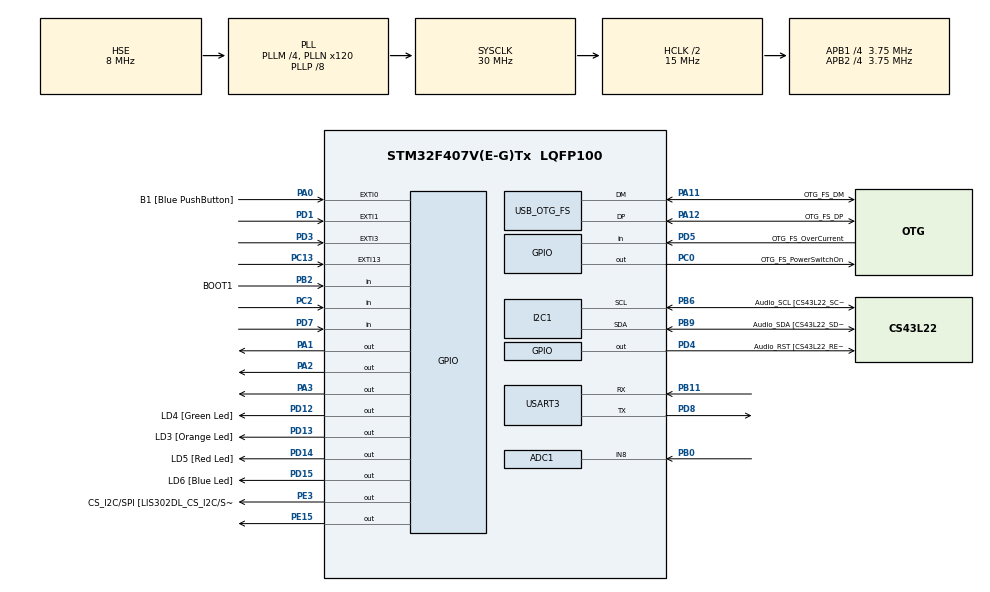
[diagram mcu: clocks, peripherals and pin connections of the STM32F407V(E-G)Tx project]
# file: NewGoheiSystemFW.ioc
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ADC1.Channel-32\#ChannelRegularConversion=ADC_CHANNEL_8
ADC1.ClockPrescaler=ADC_CLOCK_SYNC_PCLK_DIV2
ADC1.ContinuousConvMode=DISABLE
ADC1.DMAContinuousRequests=DISABLE
ADC1.DataAlign=ADC_DATAALIGN_RIGHT
ADC1.DiscontinuousConvMode=DISABLE
ADC1.EOCSelection=ADC_EOC_SINGLE_CONV
ADC1.EnableAnalogWatchDog=false
ADC1.ExternalTrigConv=ADC_SOFTWARE_START
ADC1.ExternalTrigConvEdge=ADC_EXTERNALTRIGCONVEDGE_NONE
ADC1.InjNumberOfConversion=0
ADC1.NbrOfConversion=1
ADC1.NbrOfConversionFlag=1
ADC1.Rank-32\#ChannelRegularConversion=1
ADC1.Resolution=ADC_RESOLUTION_12B
ADC1.SamplingTime-32\#ChannelRegularConversion=ADC_SAMPLETIME_3CYCLES
ADC1.ScanConvMode=DISABLE
ADC1.master=1
Dma.Request0=USART3_RX
Dma.USART3_RX.0.Direction=DMA_PERIPH_TO_MEMORY
Dma.USART3_RX.0.FIFOMode=DMA_FIFOMODE_DISABLE
Dma.USART3_RX.0.Instance=DMA1_Stream1
Dma.USART3_RX.0.MemDataAlignment=DMA_MDATAALIGN_BYTE
Dma.USART3_RX.0.MemInc=DMA_MINC_ENABLE
Dma.USART3_RX.0.Mode=DMA_CIRCULAR
Dma.USART3_RX.0.PeriphDataAlignment=DMA_PDATAALIGN_BYTE
Dma.USART3_RX.0.PeriphInc=DMA_PINC_DISABLE
Dma.USART3_RX.0.Priority=DMA_PRIORITY_LOW
Mcu.Family=STM32F4
Mcu.Name=STM32F407V(E-G)Tx
Mcu.Package=LQFP100
NVIC.ADC_IRQn=true\:0\:1\:false\:false\:true\:true
NVIC.DMA1_Stream1_IRQn=true\:0\:0\:false\:false\:true\:false
NVIC.EXTI15_10_IRQn=true\:0\:0\:false\:false\:true\:true
NVIC.EXTI1_IRQn=true\:0\:0\:false\:false\:true\:true
NVIC.EXTI3_IRQn=true\:0\:0\:false\:false\:true\:true
NVIC.OTG_FS_IRQn=true\:0\:0\:false\:false\:true\:false
NVIC.PriorityGroup=NVIC_PRIORITYGROUP_0
NVIC.TIM2_IRQn=true\:0\:0\:false\:false\:true\:true
NVIC.TIM3_IRQn=true\:0\:2\:true\:false\:true\:true
NVIC.TIM4_IRQn=true\:0\:0\:false\:false\:true\:true
PA0-WKUP.GPIO_Label=B1 [Blue PushButton]
PA0-WKUP.Signal=GPXTI0
PA1.Signal=GPIO_Output
PA10.GPIO_Label=OTG_FS_ID
PA10.GPIO_Mode=GPIO_MODE_AF_PP
PA10.GPIO_PuPd=GPIO_NOPULL
PA10.GPIO_Speed=GPIO_SPEED_FREQ_LOW
PA10.Signal=USB_OTG_FS_ID
PA11.GPIO_Label=OTG_FS_DM
PA11.GPIO_Mode=GPIO_MODE_AF_PP
PA11.GPIO_PuPd=GPIO_NOPULL
PA11.GPIO_Speed=GPIO_SPEED_FREQ_LOW
PA11.Mode=Device_Only
PA11.Signal=USB_OTG_FS_DM
PA12.GPIO_Label=OTG_FS_DP
PA12.GPIO_Mode=GPIO_MODE_AF_PP
PA12.GPIO_PuPd=GPIO_NOPULL
PA12.GPIO_Speed=GPIO_SPEED_FREQ_LOW
PA12.Mode=Device_Only
PA12.Signal=USB_OTG_FS_DP
PA13.GPIO_Label=SWDIO
PA13.Signal=SYS_JTMS-SWDIO
PA14.GPIO_Label=SWCLK
PA14.Signal=SYS_JTCK-SWCLK
PA2.Signal=GPIO_Output
PA3.Signal=GPIO_Output
PA4.GPIO_Label=I2S3_WS [CS43L22_LRCK]
PA4.GPIO_Mode=GPIO_MODE_AF_PP
PA4.GPIO_PuPd=GPIO_NOPULL
PA4.GPIO_Speed=GPIO_SPEED_FREQ_LOW
PA4.Signal=I2S3_WS
PA5.GPIO_Label=SPI1_SCK [LIS302DL_SCL/SPC]
PA5.GPIO_Mode=GPIO_MODE_AF_PP
PA5.GPIO_PuPd=GPIO_NOPULL
PA5.GPIO_Speed=GPIO_SPEED_FREQ_LOW
PA5.Signal=SPI1_SCK
PA6.GPIO_Label=SPI1_MISO [LIS302DL_SDO]
PA6.GPIO_Mode=GPIO_MODE_AF_PP
PA6.GPIO_PuPd=GPIO_NOPULL
PA6.GPIO_Speed=GPIO_SPEED_FREQ_LOW
PA6.Signal=SPI1_MISO
PA7.GPIO_Label=SPI1_MOSI [LIS302DL_SDA/SDI/SDO]
PA7.GPIO_Mode=GPIO_MODE_AF_PP
PA7.GPIO_PuPd=GPIO_NOPULL
PA7.GPIO_Speed=GPIO_SPEED_FREQ_LOW
PA7.Signal=SPI1_MOSI
PA9.GPIO_Label=VBUS_FS
PA9.GPIO_Mode=GPIO_MODE_INPUT
PA9.GPIO_PuPd=GPIO_NOPULL
PA9.Signal=USB_OTG_FS_VBUS
PB0.GPIO_Mode=GPIO_MODE_ANALOG
PB0.GPIO_PuPd=GPIO_NOPULL
PB0.Signal=ADCx_IN8
PB10.GPIO_Label=CLK_IN [MP45DT02_CLK]
PB10.GPIO_Mode=GPIO_MODE_AF_PP
PB10.GPIO_PuPd=GPIO_NOPULL
PB10.GPIO_Speed=GPIO_SPEED_FREQ_LOW
PB10.Signal=I2S2_CK
PB11.Mode=Asynchronous
PB11.Signal=USART3_RX
PB2.GPIO_Label=BOOT1
PB2.GPIO_Mode=GPIO_MODE_INPUT
PB2.GPIO_PuPd=GPIO_NOPULL
PB2.Signal=GPIO_Input
PB3.GPIO_Label=SWO
PB3.Signal=SYS_JTDO-SWO
PB6.GPIO_Label=Audio_SCL [CS43L22_SCL]
PB6.GPIO_Mode=GPIO_MODE_AF_OD
PB6.GPIO_PuPd=GPIO_NOPULL
PB6.GPIO_Speed=GPIO_SPEED_FREQ_LOW
PB6.Mode=I2C
PB6.Signal=I2C1_SCL
PB9.GPIO_Label=Audio_SDA [CS43L22_SDA]
PB9.GPIO_Mode=GPIO_MODE_AF_OD
PB9.GPIO_PuPd=GPIO_NOPULL
PB9.GPIO_Speed=GPIO_SPEED_FREQ_LOW
PB9.Mode=I2C
PB9.Signal=I2C1_SDA
PC0.GPIO_Label=OTG_FS_PowerSwitchOn
PC0.GPIO_PuPd=GPIO_NOPULL
PC0.GPIO_Speed=GPIO_SPEED_FREQ_LOW
PC0.PinState=GPIO_PIN_SET
PC0.Signal=GPIO_Output
PC10.GPIO_Label=I2S3_SCK [CS43L22_SCLK]
PC10.GPIO_Mode=GPIO_MODE_AF_PP
PC10.GPIO_PuPd=GPIO_NOPULL
PC10.GPIO_Speed=GPIO_SPEED_FREQ_LOW
PC10.Signal=I2S3_CK
PC12.GPIO_Label=I2S3_SD [CS43L22_SDIN]
PC12.GPIO_Mode=GPIO_MODE_AF_PP
PC12.GPIO_PuPd=GPIO_NOPULL
PC12.GPIO_Speed=GPIO_SPEED_FREQ_LOW
PC12.Signal=I2S3_SD
PC13-ANTI_TAMP.Signal=GPXTI13
PC14-OSC32_IN.GPIO_Label=PC14-OSC32_IN
PC14-OSC32_IN.Signal=RCC_OSC32_IN
PC15-OSC32_OUT.GPIO_Label=PC15-OSC32_OUT
PC15-OSC32_OUT.Signal=RCC_OSC32_OUT
PC2.GPIO_PuPd=GPIO_PULLUP
PC2.Signal=GPIO_Input
PC3.GPIO_Label=PDM_OUT [MP45DT02_DOUT]
PC3.GPIO_Mode=GPIO_MODE_AF_PP
PC3.GPIO_PuPd=GPIO_NOPULL
PC3.GPIO_Speed=GPIO_SPEED_FREQ_LOW
PC3.Signal=I2S2_SD
PC7.GPIO_Label=I2S3_MCK [CS43L22_MCLK]
PC7.GPIO_Mode=GPIO_MODE_AF_PP
PC7.GPIO_PuPd=GPIO_NOPULL
PC7.GPIO_Speed=GPIO_SPEED_FREQ_LOW
PC7.Signal=I2S3_MCK
PD1.GPIO_PuPd=GPIO_PULLUP
PD1.Signal=GPXTI1
PD12.GPIO_Label=LD4 [Green Led]
PD12.GPIO_PuPd=GPIO_NOPULL
PD12.GPIO_Speed=GPIO_SPEED_FREQ_LOW
PD12.Signal=GPIO_Output
PD13.GPIO_Label=LD3 [Orange Led]
PD13.GPIO_PuPd=GPIO_NOPULL
PD13.GPIO_Speed=GPIO_SPEED_FREQ_LOW
PD13.Signal=GPIO_Output
PD14.GPIO_Label=LD5 [Red Led]
PD14.GPIO_PuPd=GPIO_NOPULL
PD14.GPIO_Speed=GPIO_SPEED_FREQ_LOW
PD14.Signal=GPIO_Output
PD15.GPIO_Label=LD6 [Blue Led]
PD15.GPIO_PuPd=GPIO_NOPULL
PD15.GPIO_Speed=GPIO_SPEED_FREQ_LOW
PD15.Signal=GPIO_Output
PD3.GPIO_PuPd=GPIO_PULLUP
PD3.Signal=GPXTI3
PD4.GPIO_Label=Audio_RST [CS43L22_RESET]
PD4.GPIO_PuPd=GPIO_NOPULL
PD4.GPIO_Speed=GPIO_SPEED_FREQ_LOW
PD4.Signal=GPIO_Output
PD5.GPIO_Label=OTG_FS_OverCurrent
PD5.GPIO_Mode=GPIO_MODE_INPUT
PD5.GPIO_PuPd=GPIO_NOPULL
PD5.Signal=GPIO_Input
PD7.GPIO_PuPd=GPIO_PULLUP
PD7.Signal=GPIO_Input
PD8.Mode=Asynchronous
PD8.Signal=USART3_TX
PE15.GPIO_ModeDefaultOutputPP=GPIO_MODE_OUTPUT_OD
PE15.GPIO_Speed=GPIO_SPEED_FREQ_LOW
PE15.PinState=GPIO_PIN_SET
PE15.Signal=GPIO_Output
PE3.GPIO_Label=CS_I2C/SPI [LIS302DL_CS_I2C/SPI]
PE3.GPIO_PuPd=GPIO_NOPULL
PE3.GPIO_Speed=GPIO_SPEED_FREQ_LOW
PE3.Signal=GPIO_Output
PH0-OSC_IN.GPIO_Label=PH0-OSC_IN
PH0-OSC_IN.Mode=HSE-External-Clock-Source
PH0-OSC_IN.Signal=RCC_OSC_IN
PH1-OSC_OUT.GPIO_Label=PH1-OSC_OUT
PH1-OSC_OUT.Mode=HSE-External-Clock-Source
PH1-OSC_OUT.Signal=RCC_OSC_OUT
ProjectManager.HeapSize=0x200
ProjectManager.StackSize=0x400
ProjectManager.TargetToolchain=SW4STM32
RCC.48MHZClocksFreq_Value=48000000
RCC.AHBCLKDivider=RCC_SYSCLK_DIV2
RCC.AHBFreq_Value=15000000
RCC.APB1CLKDivider=RCC_HCLK_DIV4
RCC.APB1Freq_Value=3750000
RCC.APB1TimFreq_Value=7500000
RCC.APB2CLKDivider=RCC_HCLK_DIV4
RCC.APB2Freq_Value=3750000
RCC.APB2TimFreq_Value=7500000
RCC.CortexFreq_Value=15000000
RCC.HCLKFreq_Value=15000000
RCC.HSE_VALUE=8000000
RCC.HSI_VALUE=16000000
RCC.LSE_VALUE=32768
RCC.PLLM=4
RCC.PLLN=120
RCC.PLLP=RCC_PLLP_DIV8
RCC.PLLQ=5
RCC.SYSCLKFreq_VALUE=30000000
RCC.SYSCLKSource=RCC_SYSCLKSOURCE_PLLCLK
RCC.VCOOutputFreq_Value=240000000
SH.ADCx_IN8.0=ADC1_IN8,IN8
TIM2.Period=10000
TIM2.Prescaler=750
TIM3.Period=10000
TIM3.Prescaler=750
TIM4.Period=1000
TIM4.Prescaler=750
USART3.VirtualMode=VM_ASYNC
USB_DEVICE.CLASS_NAME_FS=CDC
USB_DEVICE.VirtualMode-CDC_FS=Cdc
USB_DEVICE.VirtualModeFS=Cdc_FS
USB_OTG_FS.VirtualMode=Device_Only
VP_TIM2_VS_ClockSourceINT.Mode=Internal
VP_TIM3_VS_ClockSourceINT.Mode=Internal
VP_TIM4_VS_ClockSourceINT.Mode=Internal
VP_USB_DEVICE_VS_USB_DEVICE_CDC_FS.Mode=CDC_FS
board=STM32F4DISCOVERY

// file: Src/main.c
/**
  ******************************************************************************
  * File Name          : main.c
  * Description        : Main program body
  ******************************************************************************
  * This notice applies to any and all portions of this file
  * that are not between comment pairs USER CODE BEGIN and
  * USER CODE END. Other portions of this file, whether
  * inserted by the user or by software development tools
  * are owned by their respective copyright owners.
  *
  * Copyright (c) 2018 STMicroelectronics International N.V.
  * All rights reserved.
  *
  * Redistribution and use in source and binary forms, with or without
  * modification, are permitted, provided that the following conditions are met:
  *
  * 1. Redistribution of source code must retain the above copyright notice,
  *    this list of conditions and the following disclaimer.
  * 2. Redistributions in binary form must reproduce the above copyright notice,
  *    this list of conditions and the following disclaimer in the documentation
  *    and/or other materials provided with the distribution.
  * 3. Neither the name of STMicroelectronics nor the names of other
  *    contributors to this software may be used to endorse or promote products
  *    derived from this software without specific written permission.
  * 4. This software, including modifications and/or derivative works of this
  *    software, must execute solely and exclusively on microcontroller or
  *    microprocessor devices manufactured by or for STMicroelectronics.
  * 5. Redistribution and use of this software other than as permitted under
  *    this license is void and will automatically terminate your rights under
  *    this license.
  *
  * THIS SOFTWARE IS PROVIDED BY STMICROELECTRONICS AND CONTRIBUTORS "AS IS"
  * AND ANY EXPRESS, IMPLIED OR STATUTORY WARRANTIES, INCLUDING, BUT NOT
  * LIMITED TO, THE IMPLIED WARRANTIES OF MERCHANTABILITY, FITNESS FOR A
  * PARTICULAR PURPOSE AND NON-INFRINGEMENT OF THIRD PARTY INTELLECTUAL PROPERTY
  * RIGHTS ARE DISCLAIMED TO THE FULLEST EXTENT PERMITTED BY LAW. IN NO EVENT
  * SHALL STMICROELECTRONICS OR CONTRIBUTORS BE LIABLE FOR ANY DIRECT, INDIRECT,
  * INCIDENTAL, SPECIAL, EXEMPLARY, OR CONSEQUENTIAL DAMAGES (INCLUDING, BUT NOT
  * LIMITED TO, PROCUREMENT OF SUBSTITUTE GOODS OR SERVICES; LOSS OF USE, DATA,
  * OR PROFITS; OR BUSINESS INTERRUPTION) HOWEVER CAUSED AND ON ANY THEORY OF
  * LIABILITY, WHETHER IN CONTRACT, STRICT LIABILITY, OR TORT (INCLUDING
  * NEGLIGENCE OR OTHERWISE) ARISING IN ANY WAY OUT OF THE USE OF THIS SOFTWARE,
  * EVEN IF ADVISED OF THE POSSIBILITY OF SUCH DAMAGE.
  *
  ******************************************************************************
  */

#include "main.h"
#include "stm32f4xx_hal.h"
#include "adc.h"
#include "dma.h"
#include "i2c.h"
#include "tim.h"
#include "usart.h"
#include "usb_device.h"
#include "gpio.h"

/* USER CODE BEGIN Includes */
#include "peripheralManualControlTest.h"
#include "boardControlTest.h"
#include "LCDDriverTest.h"
#include "USB_CDC_Test.h"
#include "WifiControlTest.h"
/* USER CODE END Includes */

/* USER CODE BEGIN PV */
/* Private variables ---------------------------------------------------------*/
/* USER CODE END PV */

void SystemClock_Config(void);

/* USER CODE BEGIN PFP */
/* Private function prototypes -----------------------------------------------*/

/* USER CODE END PFP */

int main(void)
{

  /* MCU Configuration----------------------------------------------------------*/

  /* Reset of all peripherals, Initializes the Flash interface and the Systick. */
  HAL_Init();

  /* Configure the system clock */
  SystemClock_Config();

  /* Initialize all configured peripherals */
  MX_GPIO_Init();
  MX_DMA_Init();
  MX_I2C1_Init();
  MX_ADC1_Init();
  MX_TIM3_Init();
  MX_USB_DEVICE_Init();
  MX_TIM2_Init();
  MX_TIM4_Init();
  MX_USART3_UART_Init();

  /* USER CODE BEGIN 2 */
  WifiNTPTest();
//  WifiModuleBootTest();

  //LCDDriverTest();
  boardControlTaskTest();
  USB_CDC_Test();
  /* USER CODE END 2 */

  /* Infinite loop */
  while (1)
  {

  /* USER CODE BEGIN 3 */

	  //GPIO_relay_anode_control_test();
	  //ADC_DataGet_test();
  }
  /* USER CODE END 3 */

}

/** System Clock Configuration
*/
void SystemClock_Config(void)
{

  RCC_OscInitTypeDef RCC_OscInitStruct;
  RCC_ClkInitTypeDef RCC_ClkInitStruct;

    /**Configure the main internal regulator output voltage
    */
  __HAL_RCC_PWR_CLK_ENABLE();

  __HAL_PWR_VOLTAGESCALING_CONFIG(PWR_REGULATOR_VOLTAGE_SCALE1);

    /**Initializes the CPU, AHB and APB busses clocks
    */
  RCC_OscInitStruct.OscillatorType = RCC_OSCILLATORTYPE_HSE;
  RCC_OscInitStruct.HSEState = RCC_HSE_BYPASS;
  RCC_OscInitStruct.PLL.PLLState = RCC_PLL_ON;
  RCC_OscInitStruct.PLL.PLLSource = RCC_PLLSOURCE_HSE;
  RCC_OscInitStruct.PLL.PLLM = 4;
  RCC_OscInitStruct.PLL.PLLN = 120;
  RCC_OscInitStruct.PLL.PLLP = RCC_PLLP_DIV8;
  RCC_OscInitStruct.PLL.PLLQ = 5;
  if (HAL_RCC_OscConfig(&RCC_OscInitStruct) != HAL_OK)
  {
    _Error_Handler(__FILE__, __LINE__);
  }

    /**Initializes the CPU, AHB and APB busses clocks
    */
  RCC_ClkInitStruct.ClockType = RCC_CLOCKTYPE_HCLK|RCC_CLOCKTYPE_SYSCLK
                              |RCC_CLOCKTYPE_PCLK1|RCC_CLOCKTYPE_PCLK2;
  RCC_ClkInitStruct.SYSCLKSource = RCC_SYSCLKSOURCE_PLLCLK;
  RCC_ClkInitStruct.AHBCLKDivider = RCC_SYSCLK_DIV2;
  RCC_ClkInitStruct.APB1CLKDivider = RCC_HCLK_DIV4;
  RCC_ClkInitStruct.APB2CLKDivider = RCC_HCLK_DIV4;

  if (HAL_RCC_ClockConfig(&RCC_ClkInitStruct, FLASH_LATENCY_0) != HAL_OK)
  {
    _Error_Handler(__FILE__, __LINE__);
  }

    /**Configure the Systick interrupt time
    */
  HAL_SYSTICK_Config(HAL_RCC_GetHCLKFreq()/1000);

    /**Configure the Systick
    */
  HAL_SYSTICK_CLKSourceConfig(SYSTICK_CLKSOURCE_HCLK);

  /* SysTick_IRQn interrupt configuration */
  HAL_NVIC_SetPriority(SysTick_IRQn, 0, 0);
}

void _Error_Handler(char * file, int line)
{
  while(1)
  {
  }
}

/************************ (C) COPYRIGHT STMicroelectronics *****END OF FILE****/
